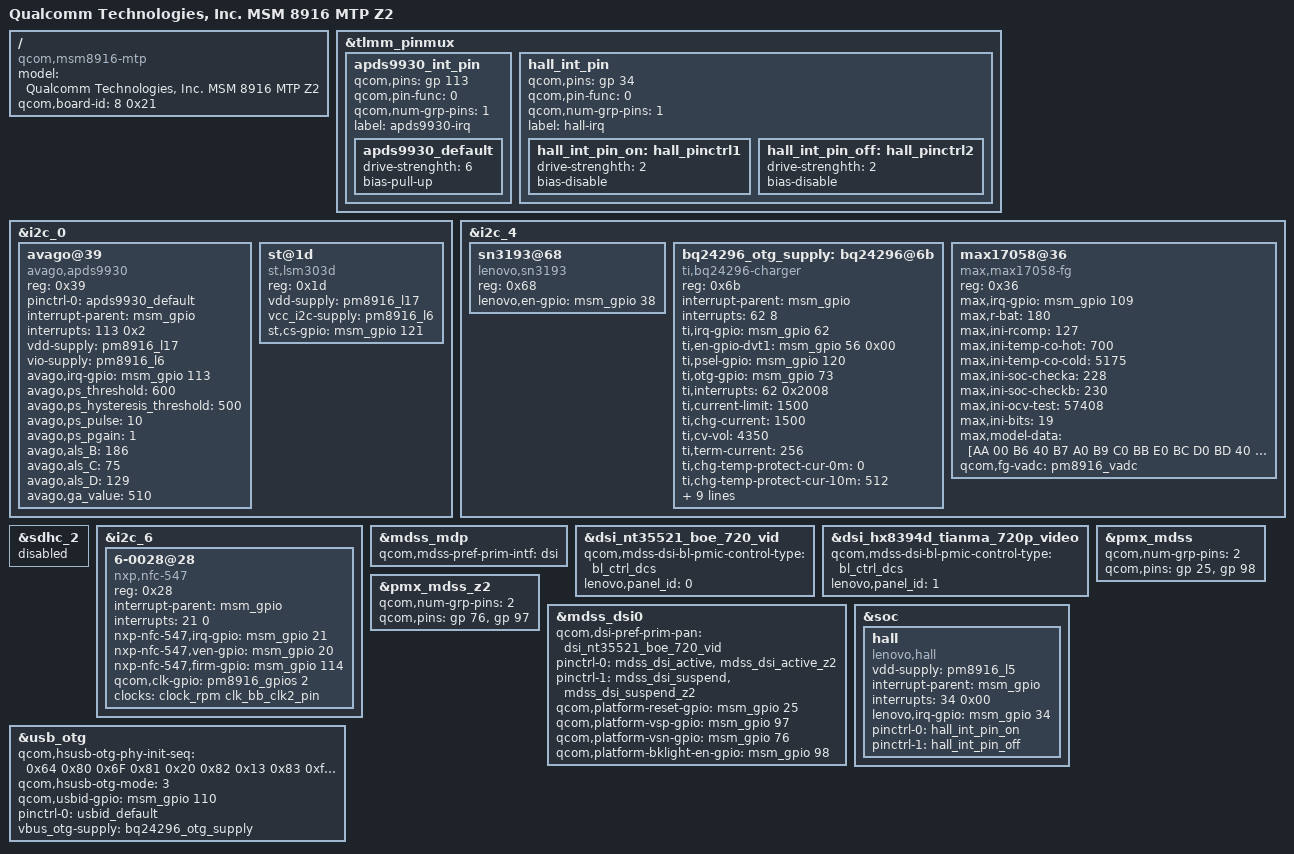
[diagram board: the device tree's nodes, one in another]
/* Copyright (c) 2014, The Linux Foundation. All rights reserved.
*
* This program is free software; you can redistribute it and/or modify
* it under the terms of the GNU General Public License version 2 and
* only version 2 as published by the Free Software Foundation.
*
* This program is distributed in the hope that it will be useful,
* but WITHOUT ANY WARRANTY; without even the implied warranty of
* MERCHANTABILITY or FITNESS FOR A PARTICULAR PURPOSE.  See the
* GNU General Public License for more details.
*/

/dts-v1/;

#include "msm8916-mtp-z2.dtsi"
#include "msm8916-memory.dtsi"

/ {
	model = "Qualcomm Technologies, Inc. MSM 8916 MTP Z2";
	compatible = "qcom,msm8916-mtp", "qcom,msm8916", "qcom,mtp", "lenovo,z2";
	qcom,board-id = <8 0x21>;
};

&tlmm_pinmux {
		apds9930_int_pin {
			qcom,pins = <&gp 113>;
			qcom,pin-func = <0>;
			qcom,num-grp-pins = <1>;
			label = "apds9930-irq";
			apds9930_default: apds9930_default {
				drive-strenghth = <6>;
				bias-pull-up;
			};
		};

	hall_int_pin {
		qcom,pins = <&gp 34>;
		qcom,pin-func = <0>;
		qcom,num-grp-pins = <1>;
		label = "hall-irq";
		hall_int_pin_on: hall_pinctrl1 {
			drive-strenghth = <2>;
			bias-disable;
		};
		hall_int_pin_off: hall_pinctrl2 {
			drive-strenghth = <2>;
			bias-disable;
		};
	};
};

&i2c_0 { /* BLSP1 QUP2 */
		avago@39 {
			compatible = "avago,apds9930";
			reg = <0x39>;
			pinctrl-names = "default";
			pinctrl-0 = <&apds9930_default>;
			interrupt-parent = <&msm_gpio>;
			interrupts = <113 0x2>;
			vdd-supply = <&pm8916_l17>;
			vio-supply = <&pm8916_l6>;
			avago,irq-gpio = <&msm_gpio 113 0x2>;
			avago,ps_threshold = <600>;
			avago,ps_hysteresis_threshold = <500>;
			avago,ps_pulse = <10>;
			avago,ps_pgain = <1>;
			avago,als_B = <186>;
			avago,als_C = <75>;
			avago,als_D = <129>;
			avago,ga_value = <510>;
		};
	/*lenovo-sw molg 20140428 add begin*/
		st@1d {
			compatible = "st,lsm303d";
			reg = <0x1d>;
			vdd-supply = <&pm8916_l17>;
			vcc_i2c-supply = <&pm8916_l6>;
			st,cs-gpio = <&msm_gpio 121 0x00>;
		};
	/*lenovo-sw molg 20140428 add end*/
};

&i2c_4 {
		sn3193@68 {
			compatible = "lenovo,sn3193";
			reg = <0x68>;
			lenovo,en-gpio = <&msm_gpio 38 0x00>;
		};

		bq24296_otg_supply: bq24296@6b {
			compatible = "ti,bq24296-charger";
			reg = <0x6b>;
			interrupt-parent = <&msm_gpio>;
			interrupts = <62 8>;
			ti,irq-gpio = <&msm_gpio 62 0x2008>;
			ti,en-gpio-dvt1 = <&msm_gpio 56 0x00>;
			ti,psel-gpio = <&msm_gpio 120 0x00>;
			ti,otg-gpio = <&msm_gpio 73 0x00>;
			ti,interrupts = <62 0x2008>;
			ti,current-limit = <1500>;
			ti,chg-current = <1500>;
			ti,cv-vol = <4350>;
			ti,term-current = <256>;
			ti,chg-temp-protect-cur-0m = <0>;
			ti,chg-temp-protect-cur-10m = <512>;
			ti,chg-temp-protect-cur-45m = <1500>;
			ti,chg-temp-protect-cur-50m = <1500>;
			ti,chg-temp-protect-cur-50p = <0>;
			ti,chg-temp-protect-vol-0m = <4350>;
			ti,chg-temp-protect-vol-10m = <4350>;
			ti,chg-temp-protect-vol-45m = <4350>;
			ti,chg-temp-protect-vol-50m = <4350>;
			ti,chg-temp-protect-vol-50p = <4350>;

                        regulator-name = "bq24296_otg_vreg";
        };

		max17058@36 {
			compatible = "max,max17058-fg";
			reg = <0x36>;
			max,irq-gpio = <&msm_gpio 109 0x2008>;
			max,r-bat = <180>;//need to calculate
			max,ini-rcomp = <127>;
			max,ini-temp-co-hot = <700>;//factor 1000
			max,ini-temp-co-cold = <5175>;//factor 1000
			max,ini-soc-checka = <228>;
			max,ini-soc-checkb = <230>;
			max,ini-ocv-test = <57408>;
			max,ini-bits = <19>;
			max,model-data = [AA 00 B6 40 B7 A0 B9 C0 
							BB E0 BC D0 BD 40 BD A0 
							C0 30 C0 F0 C4 80 C6 00 
							C8 80 CB 00 CF E0 D6 40 
							01 C0 17 60 1D A0 17 80 
							54 80 5F 80 7E A0 14 A0 
							4A 60 0E 00 22 40 10 00 
							10 00 14 00 0C 00 0C 00];
			qcom,fg-vadc = <&pm8916_vadc>;
        };	
};

&sdhc_2 {
  status = "disabled";
};

/* add by lenovo-sw2 lumy1 begin*/
&i2c_6 { /* BLSP1 QUP6 */
	6-0028@28 {
		compatible = "nxp,nfc-547";
		reg = <0x28>;
          /*
		qcom,irq-gpio = <&msm_gpio 21 0x00>;
		qcom,dis-gpio = <&msm_gpio 20 0x00>;
		qcom,clk-src = "BBCLK2";
		qcom,clk-en-gpio = <&msm_gpio 0 0x00>;
          */
		interrupt-parent = <&msm_gpio>;
		interrupts = <21 0>;
          /*
		interrupt-names = "nfc_irq";
		pinctrl-names = "nfc_active","nfc_suspend";
		pinctrl-0 = <&nfc_int_active &nfc_disable_active>;
		pinctrl-1 = <&nfc_int_suspend &nfc_disable_suspend>;
		*/
		nxp-nfc-547,irq-gpio = <&msm_gpio 21 0x00>;
		nxp-nfc-547,ven-gpio = <&msm_gpio 20 0x00>;
		nxp-nfc-547,firm-gpio = <&msm_gpio 114 0x00>;
		qcom,clk-gpio = <&pm8916_gpios 2 0>;
		clocks = <&clock_rpm clk_bb_clk2_pin>;
		clock-names = "nfc_clk";
	};
};
/* add by lenovo-sw2 lumy1 end*/

/* add bylenovo-sw2 houdz1 begin*/
#include "lenovo-tianma-dsi-panel-hx8394d-720p-video.dtsi"
#include "lenovo-boe-dsi-panel-nt35521-720p-video.dtsi"
#include "lenovo-boe-panel-mode-z2.dtsi"
#include "lenovo-boe-panel-gamma-z2.dtsi"
#include "lenovo-tianma-panel-mode-z2.dtsi"
#include "lenovo-tianma-panel-gamma-z2.dtsi"


&mdss_mdp {
	qcom,mdss-pref-prim-intf = "dsi";
};
&dsi_nt35521_boe_720_vid {
	qcom,mdss-dsi-bl-pmic-control-type = "bl_ctrl_dcs";
	lenovo,panel_id = <0>;
			/*qcom,mdss-dsi-bl-pmic-pwm-frequency = <100>;
			qcom,mdss-dsi-bl-pmic-bank-select = <0>;
			qcom,mdss-dsi-pwm-gpio = <&pm8916_mpps 4 0>;*/
};

			
&dsi_hx8394d_tianma_720p_video{
	qcom,mdss-dsi-bl-pmic-control-type = "bl_ctrl_dcs";
	lenovo,panel_id = <1>;
			/*qcom,mdss-dsi-bl-pmic-pwm-frequency = <100>;
			qcom,mdss-dsi-bl-pmic-bank-select = <0>;
			qcom,mdss-dsi-pwm-gpio = <&pm8916_mpps 4 0>;*/
};


			
&pmx_mdss {
	qcom,num-grp-pins = <2>;
	qcom,pins = <&gp 25>,<&gp 98>;
};

&pmx_mdss_z2 {
	qcom,num-grp-pins = <2>;
	qcom,pins =  <&gp 76>,<&gp 97>;
};
			
&mdss_dsi0 {
	qcom,dsi-pref-prim-pan = <&dsi_nt35521_boe_720_vid>;
	pinctrl-names = "mdss_default", "mdss_sleep";
	pinctrl-0 = <&mdss_dsi_active &mdss_dsi_active_z2>;
	pinctrl-1 = <&mdss_dsi_suspend &mdss_dsi_suspend_z2>;
			
	qcom,platform-reset-gpio = <&msm_gpio 25 0>;
			
	qcom,platform-vsp-gpio = <&msm_gpio 97 0>;
	qcom,platform-vsn-gpio = <&msm_gpio 76 0>;
	qcom,platform-bklight-en-gpio = <&msm_gpio 98 0>;
};

/* add bylenovo-sw2 houdz1 end*/

&soc {
	hall {
		status = "okay";
		compatible = "lenovo,hall";
		vdd-supply = <&pm8916_l5>;
		interrupt-parent = <&msm_gpio>;
		interrupts = <34 0x00>;
		lenovo,irq-gpio = <&msm_gpio 34 0x00>;
		/* pinctrl-states = "default"; */
		pinctrl-names = "hall_pinctrl_on", "hall_pinctrl_off";
		pinctrl-0 = <&hall_int_pin_on>;
		pinctrl-1 = <&hall_int_pin_off>;
	};
};


/* lenovo-sw yexh1, add for usb driver current setting and otg function, 2014-04-16 add begin */
&usb_otg{          
        qcom,hsusb-otg-phy-init-seq = <0x64 0x80 0x6F 0x81 0x20 0x82 0x13 0x83 0xffffffff>;
	qcom,hsusb-otg-mode = <3>;
	qcom,usbid-gpio = <&msm_gpio 110 0>;
	pinctrl-names = "default";
	pinctrl-0 = <&usbid_default>;
	vbus_otg-supply = <&bq24296_otg_supply>; //<&pm8916_l16>; // <&smb1360_otg_supply>; //<&pm8916_l16>; //
};
/* lenovo-sw yexh1 end */


